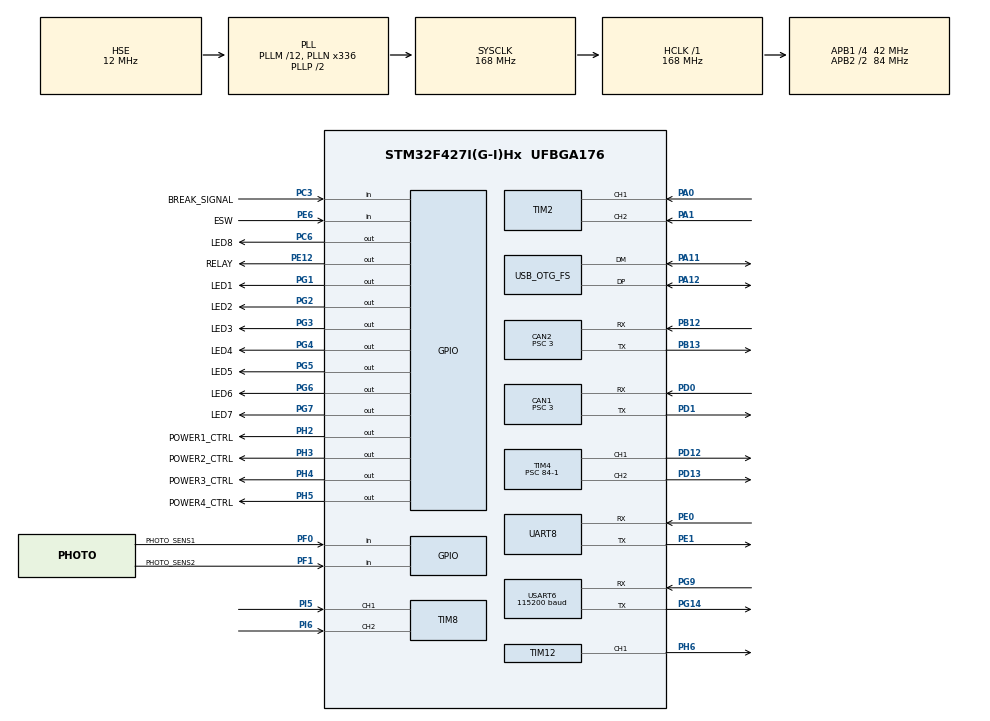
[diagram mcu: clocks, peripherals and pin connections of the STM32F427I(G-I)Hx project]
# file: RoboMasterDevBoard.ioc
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CAN1.BS1=CAN_BS1_9TQ
CAN1.BS2=CAN_BS2_4TQ
CAN1.CalculateBaudRate=1000000
CAN1.CalculateTimeBit=1000
CAN1.CalculateTimeQuantum=71.42857142857143
CAN1.Prescaler=3
CAN1.RFLM=ENABLE
CAN1.TXFP=ENABLE
CAN2.BS1=CAN_BS1_9TQ
CAN2.BS2=CAN_BS2_4TQ
CAN2.CalculateBaudRate=1000000
CAN2.CalculateTimeBit=1000
CAN2.CalculateTimeQuantum=71.42857142857143
CAN2.Prescaler=3
CAN2.RFLM=ENABLE
CAN2.TXFP=ENABLE
Dma.Request0=USART6_RX
Dma.Request1=USART6_TX
Dma.Request2=UART8_RX
Dma.Request3=UART8_TX
Dma.UART8_RX.2.Direction=DMA_PERIPH_TO_MEMORY
Dma.UART8_RX.2.FIFOMode=DMA_FIFOMODE_DISABLE
Dma.UART8_RX.2.Instance=DMA1_Stream6
Dma.UART8_RX.2.MemDataAlignment=DMA_MDATAALIGN_BYTE
Dma.UART8_RX.2.MemInc=DMA_MINC_ENABLE
Dma.UART8_RX.2.Mode=DMA_NORMAL
Dma.UART8_RX.2.PeriphDataAlignment=DMA_PDATAALIGN_BYTE
Dma.UART8_RX.2.PeriphInc=DMA_PINC_DISABLE
Dma.UART8_RX.2.Priority=DMA_PRIORITY_VERY_HIGH
Dma.UART8_TX.3.Direction=DMA_MEMORY_TO_PERIPH
Dma.UART8_TX.3.FIFOMode=DMA_FIFOMODE_DISABLE
Dma.UART8_TX.3.Instance=DMA1_Stream0
Dma.UART8_TX.3.MemDataAlignment=DMA_MDATAALIGN_BYTE
Dma.UART8_TX.3.MemInc=DMA_MINC_ENABLE
Dma.UART8_TX.3.Mode=DMA_NORMAL
Dma.UART8_TX.3.PeriphDataAlignment=DMA_PDATAALIGN_BYTE
Dma.UART8_TX.3.PeriphInc=DMA_PINC_DISABLE
Dma.UART8_TX.3.Priority=DMA_PRIORITY_VERY_HIGH
Dma.USART6_RX.0.Direction=DMA_PERIPH_TO_MEMORY
Dma.USART6_RX.0.FIFOMode=DMA_FIFOMODE_DISABLE
Dma.USART6_RX.0.Instance=DMA2_Stream1
Dma.USART6_RX.0.MemDataAlignment=DMA_MDATAALIGN_BYTE
Dma.USART6_RX.0.MemInc=DMA_MINC_ENABLE
Dma.USART6_RX.0.Mode=DMA_NORMAL
Dma.USART6_RX.0.PeriphDataAlignment=DMA_PDATAALIGN_BYTE
Dma.USART6_RX.0.PeriphInc=DMA_PINC_DISABLE
Dma.USART6_RX.0.Priority=DMA_PRIORITY_LOW
Dma.USART6_TX.1.Direction=DMA_MEMORY_TO_PERIPH
Dma.USART6_TX.1.FIFOMode=DMA_FIFOMODE_DISABLE
Dma.USART6_TX.1.Instance=DMA2_Stream6
Dma.USART6_TX.1.MemDataAlignment=DMA_MDATAALIGN_BYTE
Dma.USART6_TX.1.MemInc=DMA_MINC_ENABLE
Dma.USART6_TX.1.Mode=DMA_NORMAL
Dma.USART6_TX.1.PeriphDataAlignment=DMA_PDATAALIGN_BYTE
Dma.USART6_TX.1.PeriphInc=DMA_PINC_DISABLE
Dma.USART6_TX.1.Priority=DMA_PRIORITY_LOW
Mcu.Family=STM32F4
Mcu.Name=STM32F427I(G-I)Hx
Mcu.Package=UFBGA176
NVIC.CAN1_RX0_IRQn=true\:0\:0\:false\:false\:true\:true\:true\:true
NVIC.CAN1_RX1_IRQn=true\:0\:0\:false\:false\:true\:true\:true\:true
NVIC.CAN1_SCE_IRQn=true\:0\:0\:false\:false\:true\:true\:true\:true
NVIC.CAN1_TX_IRQn=true\:0\:0\:false\:false\:true\:true\:true\:true
NVIC.CAN2_RX0_IRQn=true\:0\:0\:false\:false\:true\:true\:true\:true
NVIC.CAN2_RX1_IRQn=true\:0\:0\:false\:false\:true\:true\:true\:true
NVIC.CAN2_SCE_IRQn=true\:0\:0\:false\:false\:true\:true\:true\:true
NVIC.CAN2_TX_IRQn=true\:0\:0\:false\:false\:true\:true\:true\:true
NVIC.DMA1_Stream0_IRQn=true\:0\:0\:false\:false\:true\:false\:true\:true
NVIC.DMA1_Stream6_IRQn=true\:0\:0\:false\:false\:true\:false\:true\:true
NVIC.DMA2_Stream1_IRQn=true\:0\:0\:true\:false\:true\:false\:true\:true
NVIC.DMA2_Stream6_IRQn=true\:0\:0\:false\:false\:true\:false\:true\:true
NVIC.OTG_FS_IRQn=true\:1\:0\:true\:false\:true\:false\:true\:true
NVIC.PriorityGroup=NVIC_PRIORITYGROUP_4
NVIC.TIM8_TRG_COM_TIM14_IRQn=true\:1\:0\:true\:false\:true\:true\:true\:true
NVIC.UART8_IRQn=true\:0\:0\:true\:false\:true\:true\:true\:true
NVIC.USART6_IRQn=true\:1\:0\:true\:false\:true\:true\:true\:true
PA0/WKUP.Signal=S_TIM2_CH1_ETR
PA1.Signal=S_TIM2_CH2
PA11.Mode=Device_Only
PA11.Signal=USB_OTG_FS_DM
PA12.Mode=Device_Only
PA12.Signal=USB_OTG_FS_DP
PA13.Mode=Serial_Wire
PA13.Signal=SYS_JTMS-SWDIO
PA14.Mode=Serial_Wire
PA14.Signal=SYS_JTCK-SWCLK
PB12.Mode=CAN_Activate
PB12.Signal=CAN2_RX
PB13.Mode=CAN_Activate
PB13.Signal=CAN2_TX
PC3.GPIO_Label=BREAK_SIGNAL
PC3.Signal=GPIO_Input
PC6.GPIO_Label=LED8
PC6.Signal=GPIO_Output
PD0.Mode=CAN_Activate
PD0.Signal=CAN1_RX
PD1.Mode=CAN_Activate
PD1.Signal=CAN1_TX
PD12.Signal=S_TIM4_CH1
PD13.Signal=S_TIM4_CH2
PE0.Mode=Asynchronous
PE0.Signal=UART8_RX
PE1.Mode=Asynchronous
PE1.Signal=UART8_TX
PE12.GPIO_Label=RELAY
PE12.Signal=GPIO_Output
PE6.GPIO_Label=ESW
PE6.GPIO_PuPd=GPIO_PULLUP
PE6.Signal=GPIO_Input
PF0.GPIO_Label=PHOTO_SENS1
PF0.GPIO_PuPd=GPIO_PULLUP
PF0.Signal=GPIO_Input
PF1.GPIO_Label=PHOTO_SENS2
PF1.GPIO_PuPd=GPIO_PULLUP
PF1.Signal=GPIO_Input
PG1.GPIO_Label=LED1
PG1.Signal=GPIO_Output
PG14.Mode=Asynchronous
PG14.Signal=USART6_TX
PG2.GPIO_Label=LED2
PG2.Signal=GPIO_Output
PG3.GPIO_Label=LED3
PG3.Signal=GPIO_Output
PG4.GPIO_Label=LED4
PG4.Signal=GPIO_Output
PG5.GPIO_Label=LED5
PG5.Signal=GPIO_Output
PG6.GPIO_Label=LED6
PG6.Signal=GPIO_Output
PG7.GPIO_Label=LED7
PG7.Signal=GPIO_Output
PG9.Mode=Asynchronous
PG9.Signal=USART6_RX
PH0/OSC_IN.Mode=HSE-External-Oscillator
PH0/OSC_IN.Signal=RCC_OSC_IN
PH1/OSC_OUT.Mode=HSE-External-Oscillator
PH1/OSC_OUT.Signal=RCC_OSC_OUT
PH2.GPIO_Label=POWER1_CTRL
PH2.Signal=GPIO_Output
PH3.GPIO_Label=POWER2_CTRL
PH3.Signal=GPIO_Output
PH4.GPIO_Label=POWER3_CTRL
PH4.Signal=GPIO_Output
PH5.GPIO_Label=POWER4_CTRL
PH5.Signal=GPIO_Output
PH6.Signal=S_TIM12_CH1
PI5.Signal=S_TIM8_CH1
PI6.Signal=S_TIM8_CH2
ProjectManager.HeapSize=0x200
ProjectManager.StackSize=0x400
ProjectManager.TargetToolchain=STM32CubeIDE
RCC.48MHZClocksFreq_Value=48000000
RCC.AHBFreq_Value=168000000
RCC.APB1CLKDivider=RCC_HCLK_DIV4
RCC.APB1Freq_Value=42000000
RCC.APB1TimFreq_Value=84000000
RCC.APB2CLKDivider=RCC_HCLK_DIV2
RCC.APB2Freq_Value=84000000
RCC.APB2TimFreq_Value=168000000
RCC.CortexFreq_Value=168000000
RCC.HCLKFreq_Value=168000000
RCC.HSE_VALUE=12000000
RCC.HSI_VALUE=16000000
RCC.LSE_VALUE=32768
RCC.PLLM=12
RCC.PLLN=336
RCC.PLLQ=7
RCC.SYSCLKFreq_VALUE=168000000
RCC.SYSCLKSource=RCC_SYSCLKSOURCE_PLLCLK
RCC.VCOOutputFreq_Value=336000000
SH.S_TIM12_CH1.0=TIM12_CH1,PWM Generation1 CH1
SH.S_TIM2_CH1_ETR.0=TIM2_CH1,Encoder_Interface
SH.S_TIM2_CH2.0=TIM2_CH2,Encoder_Interface
SH.S_TIM4_CH1.0=TIM4_CH1,PWM Generation1 CH1
SH.S_TIM4_CH2.0=TIM4_CH2,PWM Generation2 CH2
SH.S_TIM8_CH1.0=TIM8_CH1,Encoder_Interface
SH.S_TIM8_CH2.0=TIM8_CH2,Encoder_Interface
TIM12.Channel-PWM\ Generation1\ CH1=TIM_CHANNEL_1
TIM14.Period=1000-1
TIM14.Prescaler=84-1
TIM4.Channel-PWM\ Generation1\ CH1=TIM_CHANNEL_1
TIM4.Channel-PWM\ Generation2\ CH2=TIM_CHANNEL_2
TIM4.Period=20000
TIM4.Prescaler=84-1
UART8.VirtualMode=Asynchronous
USART6.BaudRate=115200
USART6.Parity=PARITY_NONE
USART6.VirtualMode=VM_ASYNC
USB_DEVICE.CLASS_NAME_FS=CDC
USB_DEVICE.VirtualMode-CDC_FS=Cdc
USB_DEVICE.VirtualModeFS=Cdc_FS
USB_OTG_FS.VirtualMode=Device_Only
VP_TIM14_VS_ClockSourceINT.Mode=Enable_Timer
VP_USB_DEVICE_VS_USB_DEVICE_CDC_FS.Mode=CDC_FS
board=custom

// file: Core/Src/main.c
/* USER CODE BEGIN Header */
/**
  ******************************************************************************
  * @file           : main.c
  * @brief          : Main program body
  ******************************************************************************
  * @attention
  *
  * Copyright (c) 2024 STMicroelectronics.
  * All rights reserved.
  *
  * This software is licensed under terms that can be found in the LICENSE file
  * in the root directory of this software component.
  * If no LICENSE file comes with this software, it is provided AS-IS.
  *
  ******************************************************************************
  */
/* USER CODE END Header */
#include "main.h"
#include "can.h"
#include "dma.h"
#include "tim.h"
#include "usart.h"
#include "usb_device.h"
#include "gpio.h"

/* USER CODE BEGIN Includes */
#include "core_utils.h"
/* USER CODE END Includes */

void SystemClock_Config(void);

/* USER CODE BEGIN 0 */
int _write(int file, char *ptr, int len)
 {
 //int DataIdx;

 HAL_UART_Transmit_DMA(&huart6, (uint8_t *)ptr, len);
/*
 for (DataIdx = 0; DataIdx < len; DataIdx++)
 {
	 //__io_putchar(*ptr++);
	 ITM_SendChar(*ptr++);
 }
 */
 return len;
 }
/* USER CODE END 0 */

int main(void)
{

  /* MCU Configuration--------------------------------------------------------*/

  /* Reset of all peripherals, Initializes the Flash interface and the Systick. */
  HAL_Init();

  /* Configure the system clock */
  SystemClock_Config();

  /* Initialize all configured peripherals */
  MX_GPIO_Init();
  MX_DMA_Init();
  MX_CAN1_Init();
  MX_TIM14_Init();
  MX_USB_DEVICE_Init();
  MX_TIM2_Init();
  MX_TIM8_Init();
  MX_TIM4_Init();
  MX_USART6_UART_Init();
  MX_UART8_Init();
  MX_TIM12_Init();
  MX_CAN2_Init();
  /* USER CODE BEGIN 2 */
  Init();

  /* USER CODE END 2 */

  /* Infinite loop */
  while (1)
  {

    /* USER CODE BEGIN 3 */
	  Loop();
  }
  /* USER CODE END 3 */
}

void SystemClock_Config(void)
{
  RCC_OscInitTypeDef RCC_OscInitStruct = {0};
  RCC_ClkInitTypeDef RCC_ClkInitStruct = {0};

  /** Configure the main internal regulator output voltage
  */
  __HAL_RCC_PWR_CLK_ENABLE();
  __HAL_PWR_VOLTAGESCALING_CONFIG(PWR_REGULATOR_VOLTAGE_SCALE1);

  /** Initializes the RCC Oscillators according to the specified parameters
  * in the RCC_OscInitTypeDef structure.
  */
  RCC_OscInitStruct.OscillatorType = RCC_OSCILLATORTYPE_HSE;
  RCC_OscInitStruct.HSEState = RCC_HSE_ON;
  RCC_OscInitStruct.PLL.PLLState = RCC_PLL_ON;
  RCC_OscInitStruct.PLL.PLLSource = RCC_PLLSOURCE_HSE;
  RCC_OscInitStruct.PLL.PLLM = 12;
  RCC_OscInitStruct.PLL.PLLN = 336;
  RCC_OscInitStruct.PLL.PLLP = RCC_PLLP_DIV2;
  RCC_OscInitStruct.PLL.PLLQ = 7;
  if (HAL_RCC_OscConfig(&RCC_OscInitStruct) != HAL_OK)
  {
    Error_Handler();
  }

  /** Initializes the CPU, AHB and APB buses clocks
  */
  RCC_ClkInitStruct.ClockType = RCC_CLOCKTYPE_HCLK|RCC_CLOCKTYPE_SYSCLK
                              |RCC_CLOCKTYPE_PCLK1|RCC_CLOCKTYPE_PCLK2;
  RCC_ClkInitStruct.SYSCLKSource = RCC_SYSCLKSOURCE_PLLCLK;
  RCC_ClkInitStruct.AHBCLKDivider = RCC_SYSCLK_DIV1;
  RCC_ClkInitStruct.APB1CLKDivider = RCC_HCLK_DIV4;
  RCC_ClkInitStruct.APB2CLKDivider = RCC_HCLK_DIV2;

  if (HAL_RCC_ClockConfig(&RCC_ClkInitStruct, FLASH_LATENCY_5) != HAL_OK)
  {
    Error_Handler();
  }
}

void Error_Handler(void)
{
  __disable_irq();
  while (1)
  {
  }
}
